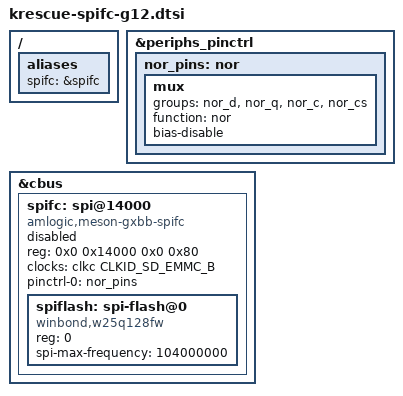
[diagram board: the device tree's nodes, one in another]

// SPIFC support

&periphs_pinctrl {
			nor_pins: nor {
			mux {
			    groups = "nor_d",
			    "nor_q",
			    "nor_c",
			    "nor_cs";
			    function = "nor";
			    bias-disable;
			};
		    };
};


&cbus {
    spifc: spi@14000 {
    compatible = "amlogic,meson-gxbb-spifc";
    reg = <0x0 0x14000 0x0 0x80>;
    #address-cells = <1>;
    #size-cells = <0>;
//  clocks = <&clkc CLKID_SPI>;
    clocks = <&clkc CLKID_SD_EMMC_B>;
    status = "disabled";
    };
};


&spifc {
//  status = "okay";
    status = "disabled";
    pinctrl-0 = <&nor_pins>;
    pinctrl-names = "default";

    spiflash: spi-flash@0 {
    #address-cells = <1>;
    #size-cells = <1>;
    compatible = "winbond,w25q128fw", "jedec,spi-nor";
    reg = <0>;
    spi-max-frequency = <104000000>;
    };
};

/ {
    aliases {
	spifc = &spifc;
    };
};
